# STM32N657 register map
File version: 1.0
CPU: CM55 r0p1, little endian, no MPU, FPU, vendor SysTick, 8 interrupt priority bits
Registers are 32-bit, read-write, reset 0x0 unless marked. A register's access mark holds for its fields unless they carry their own. Offsets are from the block's base; [hi:lo] are bit positions; {n}, {i} and the like mark numbered series; 'fields as' and 'values as' point back to an identical list.

## FDCAN1 — FDCAN register block
Base 0x4000A000
Same registers: FDCAN2 0x4000A400, FDCAN3 0x4000E800, FDCAN1_S 0x5000A000, FDCAN2_S 0x5000A400, FDCAN3_S 0x5000E800
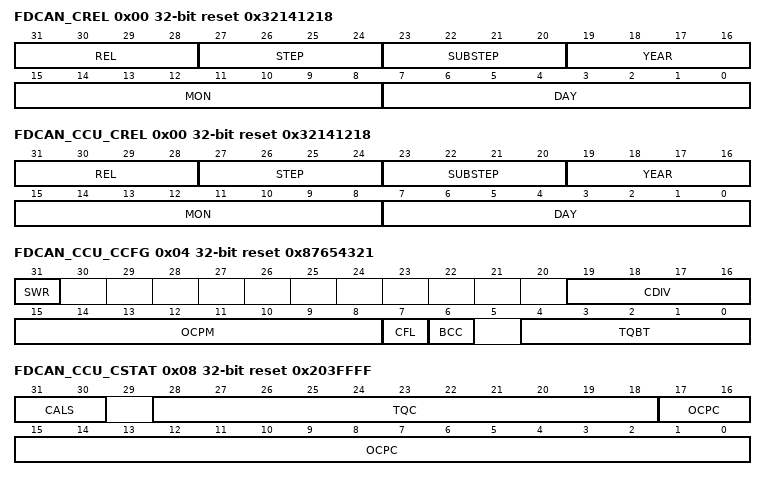
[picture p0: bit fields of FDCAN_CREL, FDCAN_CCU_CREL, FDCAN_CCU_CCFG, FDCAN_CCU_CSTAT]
0x00 FDCAN_CREL ro reset 0x32141218 — FDCAN core release register
  [31:28] REL — Core release = 3
  [27:24] STEP — Step of core release = 2
  [23:20] SUBSTEP — Sub-step of core release = 1
  [19:16] YEAR — Timestamp year = 4
  [15:8] MON — Timestamp month = 12
  [7:0] DAY — Timestamp day =18
0x00 FDCAN_CCU_CREL ro reset 0x32141218 (alternate view of FDCAN_CREL) — FDCAN core release register
  [31:28] REL — Core release = 1
  [27:24] STEP — Step of core release = 1
  [23:20] SUBSTEP — Sub-step of core release = 1
  [19:16] YEAR — Timestamp year =
  [15:8] MON — Timestamp month = 12
  [7:0] DAY — Timestamp day = 18
0x04 FDCAN_ENDN ro reset 0x87654321 — FDCAN Endian register
  [31:0] ETV — Endiannes Test value
0x04 FDCAN_CCU_CCFG reset 0x87654321 (alternate view of FDCAN_ENDN) — FDCAN Endian register
  [31] SWR — Software reset
  [19:16] CDIV — Clock divider
    0=Divide by 1; 1=Divide by 2; 2=Divide by 4; 3=Divide by 6; 4=Divide by 8; 5=Divide by 10; 6=Divide by 12; 7=Divide by 14; 8=Divide by 16; 9=Divide by 18; 10=Divide by 20; 11=Divide by 22; 12=Divide by 24; 13=Divide by 26; 14=Divide by 28; 15=Divide by 30
  [15:8] OCPM — Oscillator clock periods minimum
  [7] CFL — Calibration field length
    0=Calibration field length is 32 bits; 1=Calibration field length is 64 bits
  [6] BCC — Bypass clock calibration
    0=Clock calibration unit generates time quanta clock; 1=Clock calibration unit bypassed (default configuration)
  [4:0] TQBT — Time quanta per bit time
0x08 FDCAN_CCU_CSTAT ro reset 0x203FFFF — Calibration status register
  [31:30] CALS — Calibration state
    0=Not_Calibrated; 1=Basic_Calibrated; 2=Precision_Calibrated
  [28:18] TQC — Time quanta counter
  [17:0] OCPC — Oscillator clock period counter
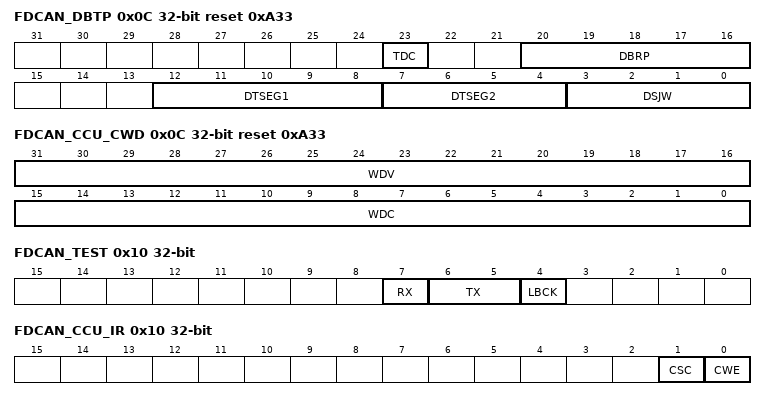
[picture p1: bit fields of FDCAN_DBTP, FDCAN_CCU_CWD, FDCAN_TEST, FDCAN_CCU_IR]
0x0C FDCAN_DBTP reset 0xA33 — FDCAN data bit timing and prescaler register
  [23] TDC — Transceiver delay compensation
    0=Transceiver delay compensation disabled; 1=Transceiver delay compensation enabled
  [20:16] DBRP — Data bitrate prescaler
  [12:8] DTSEG1 — Data time segment before sample point
  [7:4] DTSEG2 — Data time segment after sample point
  [3:0] DSJW — Synchronization jump width
0x0C FDCAN_CCU_CWD access per field reset 0xA33 (alternate view of FDCAN_DBTP) — FDCAN data bit timing and prescaler register
  [31:16] WDV ro — Watchdog value
  [15:0] WDC rw
0x10 FDCAN_TEST access per field
  [7] RX ro — Receive pin
    0=The CAN bus is dominant (FDCANx_RX = 0); 1=The CAN bus is recessive (FDCANx_RX = 1)
  [6:5] TX rw — Control of transmit pin
    0=Reset value , FDCANx_TX TX is controlled by the CAN core, updated at the end of the CAN bit time; 1=Sample point can be monitored at pin FDCANx_TX; 2=Dominant (0) level at pin FDCANx_TX; 3=Recessive (1) at pin FDCANx_TX
  [4] LBCK rw — Loop back mode
    0=Reset value, loop back mode is disabled; 1=Loop back mode is enabled (see Test modes)
0x10 FDCAN_CCU_IR (alternate view of FDCAN_TEST) — FDCAN test register
  [1] CSC — Calibration state changed
    0=Calibration state unchanged; 1=Calibration state has changed
  [0] CWE — Calibration watchdog event
    0=No calibration watchdog event; 1=Calibration watchdog event occurred
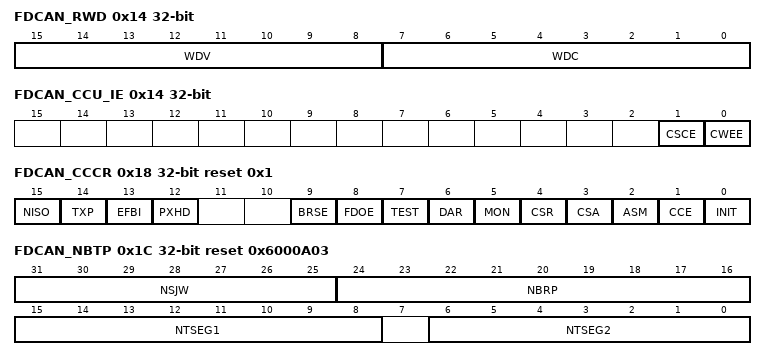
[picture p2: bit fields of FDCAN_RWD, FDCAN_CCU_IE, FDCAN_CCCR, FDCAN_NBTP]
0x14 FDCAN_RWD access per field — FDCAN RAM watchdog register
  [15:8] WDV ro — Watchdog value
  [7:0] WDC rw — Watchdog configuration
0x14 FDCAN_CCU_IE (alternate view of FDCAN_RWD) — FDCAN RAM watchdog register
  [1] CSCE — Calibration state changed enable
    0=Interrupt disabled; 1=Interrupt enabled
  [0] CWEE — Calibration watchdog event enable
    0=Interrupt disabled; 1=Interrupt enabled
0x18 FDCAN_CCCR access per field reset 0x1 — FDCAN CC control register
  [15] NISO rw — Non ISO operation
    0=CAN FD frame format according to ISO11898-1; 1=CAN FD frame format according to Bosch CAN FD Specification V1.0
  [14] TXP rw — If this bit is set, the FDCAN pauses for two CAN bit times before starting the next transmission after successfully transmitting a frame.
    0=Disabled; 1=Enabled
  [13] EFBI rw — Edge filtering during bus integration
    0=Edge filtering disabled; 1=Two consecutive dominant tq required to detect an edge for hard synchronization
  [12] PXHD rw — Protocol exception handling disable
    0=Protocol exception handling enabled; 1=Protocol exception handling disabled
  [9] BRSE rw — FDCAN bitrate switching
    0=Bitrate switching for transmissions disabled; 1=Bitrate switching for transmissions enabled
  [8] FDOE rw — FD operation enable
    0=FD operation disabled; 1=FD operation enabled
  [7] TEST rw — Test mode enable
    0=Normal operation, register TEST holds reset values; 1=Test mode, write access to register TEST enabled
  [6] DAR rw — Disable automatic retransmission
    0=Automatic retransmission of messages not transmitted successfully enabled; 1=Automatic retransmission disabled
  [5] MON rw — Bus monitoring mode
    0=Bus monitoring mode is disabled; 1=Bus monitoring mode is enabled
  [4] CSR rw — Clock stop request
    0=No clock stop is requested; 1=Clock stop requested. When clock stop is requested, first INIT and then CSA is set
  [3] CSA ro — Clock stop acknowledge
    0=No clock stop acknowledged; 1=FDCAN may be set in power down by stopping APB clock and kernel clock
  [2] ASM rw — ASM restricted operation mode
    0=Normal CAN operation; 1=Restricted operation mode active
  [1] CCE rw — Configuration change enable
    0=The CPU has no write access to the protected configuration registers; 1=The CPU has write access to the protected configuration registers (while FDCAN_CCCR.INIT = 1 CCE bit is automatically cleared when INIT bit is cleared)
  [0] INIT rw — Initialization
    0=Normal operation; 1=Initialization is started (while FDCAN_CCCR.INIT = 1 CCE bit is automatically cleared when INIT bit is cleared)
0x1C FDCAN_NBTP reset 0x6000A03 — FDCAN nominal bit timing and prescaler register
  [31:25] NSJW — Nominal (re)synchronization jump width
  [24:16] NBRP — Bitrate prescaler
  [15:8] NTSEG1 — Nominal time segment before sample point
  [6:0] NTSEG2 — Nominal time segment after sample point
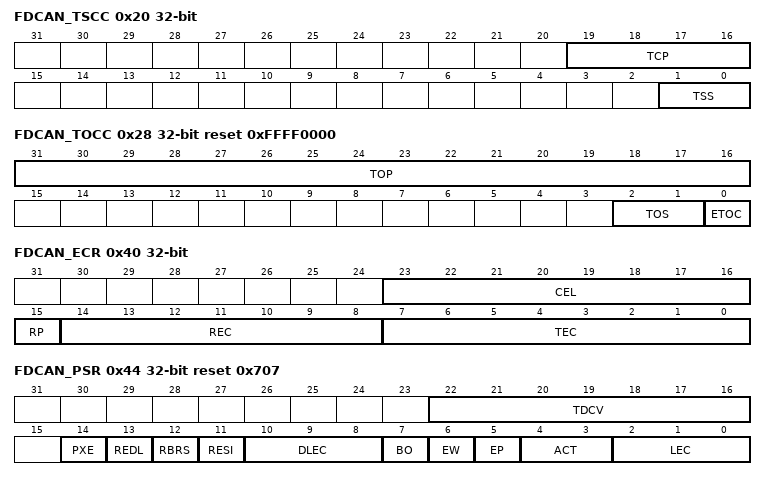
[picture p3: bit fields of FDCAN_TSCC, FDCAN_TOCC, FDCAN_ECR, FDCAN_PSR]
0x20 FDCAN_TSCC — FDCAN timestamp counter configuration register
  [19:16] TCP — Timestamp counter prescaler
  [1:0] TSS — Timestamp select
    0=Timestamp counter value always 0x0000; 1=Timestamp counter value incremented according to TCP; 2=External timestamp counter from TIM3 value used (tim3_cnt[0:15]); 3=Same as 00
0x24 FDCAN_TSCV — FDCAN timestamp counter value register
  [15:0] TSC — Timestamp counter
0x28 FDCAN_TOCC reset 0xFFFF0000 — FDCAN timeout counter configuration register
  [31:16] TOP — Timeout period
  [2:1] TOS — Timeout select
    0=Continuous operation; 1=Timeout controlled by Tx event FIFO; 2=Timeout controlled by Rx FIFO 0; 3=Timeout controlled by Rx FIFO 1
  [0] ETOC — Enable timeout counter
    0=Timeout counter disabled; 1=Timeout counter enabled
0x2C FDCAN_TOCV reset 0xFFFF — FDCAN timeout counter value register
  [15:0] TOC — Timeout counter
0x40 FDCAN_ECR access per field — FDCAN error counter register
  [23:16] CEL rw — CAN error logging
  [15] RP ro — Receive error passive
    0=The receive error counter is below the error passive level of 128; 1=The receive error counter has reached the error passive level of 128
  [14:8] REC ro — Receive error counter
  [7:0] TEC ro — Transmit error counter
0x44 FDCAN_PSR access per field reset 0x707 — FDCAN protocol status register
  [22:16] TDCV ro — Transmitter delay compensation value
  [14] PXE rw — Protocol exception event
    0=No protocol exception event occurred since last read access; 1=Protocol exception event occurred
  [13] REDL rw — Received FDCAN message
    0=Since this bit was reset by the CPU, no FDCAN message has been received; 1=Message in FDCAN format with EDL flag set has been received
  [12] RBRS rw — BRS flag of last received FDCAN message
    0=Last received FDCAN message did not have its BRS flag set; 1=Last received FDCAN message had its BRS flag set
  [11] RESI rw — ESI flag of last received FDCAN message
    0=Last received FDCAN message did not ha ve its ESI flag set; 1=Last received FDCAN message had its ESI flag set
  [10:8] DLEC ro — Data last error code
  [7] BO ro — Bus_Off status
    0=The FDCAN is not Bus_Off; 1=The FDCAN is in Bus_Off state
  [6] EW ro — Warning status
    0=Both error counters are below the Error_Warning limit of 96; 1=At least one of error counter has reached the Error_Warning limit of 96
  [5] EP ro — Error passive
    0=The FDCAN is in the Error_Active state. It normally takes part in bus communication and sends an active error flag when an error has been detected; 1=The FDCAN is in the Error_Passive state
  [4:3] ACT ro — Activity
    0=Synchronizing: node is synchronizing on CAN communication; 1=Idle: node is neither receiver nor transmitter; 2=Receiver: node is operating as receiver; 3=Transmitter: node is operating as transmitter
  [2:0] LEC ro — Last error code
    0=No error: No error occurred since LEC has been reset by successful reception or transmission; 1=Stuff error: More than 5 equal bits in a sequence have occurred in a part of a received message where this is not allowed; 2=Form error: A fixed format part of a received frame has the wrong format; 3=AckError: The message transmitted by the FDCAN was not acknowledged by another node; 4=Bit1Error: During the transmission of a message (with the exception of the arbitration field), the device wanted to send a recessive level (bit of logical value 1), but the monitored bus value was dominant; 5=Bit0Error: During the transmission of a message (or acknowledge bit, or active error flag, or overload flag), the device wanted to send a dominant level (data or identifier bit logical value 0), but the monitored bus value was recessive. During Bus_Off recovery this status is set each time a sequence of 11 recessive bits has been monitored. This enables the CPU to monitor the proceeding of the Bus_Off recovery sequence (indicating the bus is not stuck at dominant or continuously disturbed).; 6=CRCError: The CRC check sum of a received message was incorrect. The CRC of an incoming message does not match with the CRC calculated from the received data.; 7=NoChange: Any read access to the protocol status register re-initializes the LEC to 7. When the LEC shows the value 7, no CAN bus event was detected since the last CPU read access to the protocol status register.
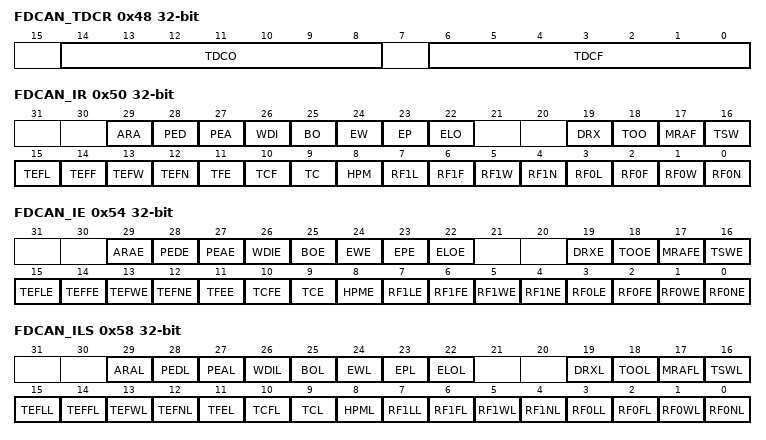
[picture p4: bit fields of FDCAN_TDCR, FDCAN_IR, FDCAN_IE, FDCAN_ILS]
0x48 FDCAN_TDCR — FDCAN transmitter delay compensation register
  [14:8] TDCO — Transmitter delay compensation offset
  [6:0] TDCF — Transmitter delay compensation filter window length
0x50 FDCAN_IR — FDCAN interrupt register
  [29] ARA — Access to reserved address
    0=No access to reserved address occurred; 1=Access to reserved address occurred
  [28] PED — Protocol error in data phase (data bit time is used)
    0=No protocol error in data phase; 1=Protocol error in data phase detected (PSR.DLEC different from 0,7)
  [27] PEA — Protocol error in arbitration phase (nominal bit time is used)
    0=No protocol error in arbitration phase; 1=Protocol error in arbitration phase detected (PSR.LEC different from 0,7)
  [26] WDI — Watchdog interrupt
    0=No message RAM watchdog event occurred; 1=Message RAM watchdog event due to missing READY
  [25] BO — Bus_Off status
    0=Bus_Off status unchanged; 1=Bus_Off status changed
  [24] EW — Warning status
    0=Error_Warning status unchanged; 1=Error_Warning status changed
  [23] EP — Error passive
    0=Error_Passive status unchanged; 1=Error_Passive status changed
  [22] ELO — Error logging overflow
    0=CAN error logging counter did not overflow; 1=Overflow of CAN error logging counter occurred
  [19] DRX — Message stored to dedicated Rx buffer
    0=No Rx buffer updated; 1=At least one received message stored into a Rx buffer
  [18] TOO — Timeout occurred
    0=No timeout; 1=Timeout reached
  [17] MRAF — Message RAM access failure
    0=No message RAM access failure occurred; 1=Message RAM access failure occurred
  [16] TSW — Timestamp wraparound
    0=No timestamp counter wraparound; 1=Timestamp counter wraparound
  [15] TEFL — Tx event FIFO element lost
    0=No Tx event FIFO element lost; 1=Tx event FIFO element lost, also set after write attempt to Tx event FIFO of size 0
  [14] TEFF — Tx event FIFO full
    0=Tx event FIFO not full; 1=Tx event FIFO full
  [13] TEFW — Tx event FIFO watermark reached
    0=Tx event FIFO fill level below watermark; 1=Tx event FIFO fill level reached watermark
  [12] TEFN — Tx event FIFO new entry
    0=Tx event FIFO unchanged; 1=Tx handler wrote Tx event FIFO element
  [11] TFE — Tx FIFO empty
    0=Tx FIFO non-empty; 1=Tx FIFO empty
  [10] TCF — Transmission cancellation finished
    0=No transmission cancellation finished; 1=Transmission cancellation finished
  [9] TC — Transmission completed
    0=No transmission completed; 1=Transmission completed
  [8] HPM — High priority message
    0=No high priority message received; 1=High priority message received
  [7] RF1L — Rx FIFO 1 message lost
    0=No Rx FIFO 1 message lost; 1=Rx FIFO 1 message lost, also set after write attempt to Rx FIFO 1 of size 0
  [6] RF1F — Rx FIFO 1 full
    0=Rx FIFO 1 not full; 1=Rx FIFO 1 full
  [5] RF1W — Rx FIFO 1 watermark reached
    0=Rx FIFO 1 fill level below watermark; 1=Rx FIFO 1 fill level reached watermark
  [4] RF1N — Rx FIFO 1 new message
    0=No new message written to Rx FIFO 1; 1=New message written to Rx FIFO 1
  [3] RF0L — Rx FIFO 0 message lost
    0=No Rx FIFO 0 message lost; 1=Rx FIFO 0 message lost, also set after write attempt to Rx FIFO 0 of size 0
  [2] RF0F — Rx FIFO 0 full
    0=Rx FIFO 0 not full; 1=Rx FIFO 0 full
  [1] RF0W — Rx FIFO 0 watermark reached
    0=Rx FIFO 0 fill level below watermark; 1=Rx FIFO 0 fill level reached watermark
  [0] RF0N — Rx FIFO 0 New message
    0=No new message written to Rx FIFO 0; 1=New message written to Rx FIFO 0
0x54 FDCAN_IE — FDCAN interrupt enable register
  [29] ARAE — Access to Reserved address enable
  [28] PEDE — Protocol error in data phase enable
  [27] PEAE — Protocol error in Arbitration phase enable
  [26] WDIE — Watchdog interrupt enable
    0=Interrupt disabled; 1=Interrupt enabled
  [25] BOE — Bus_Off status
    0=Interrupt disabled; 1=Interrupt enabled
  [24] EWE — Warning status interrupt enable
    0=Interrupt disabled; 1=Interrupt enabled
  [23] EPE — Error passive interrupt enable
    0=Interrupt disabled; 1=Interrupt enabled
  [22] ELOE — Error logging overflow interrupt enable
    0=Interrupt disabled; 1=Interrupt enabled
  [19] DRXE — Message stored to dedicated Rx buffer interrupt enable
    0=Interrupt disabled; 1=Interrupt enabled
  [18] TOOE — Timeout occurred interrupt enable
    0=Interrupt disabled; 1=Interrupt enabled
  [17] MRAFE — Message RAM access failure interrupt enable
    0=Interrupt disabled; 1=Interrupt enabled
  [16] TSWE — Timestamp wraparound interrupt enable
    0=Interrupt disabled; 1=Interrupt enabled
  [15] TEFLE — Tx event FIFO element lost interrupt enable
    0=Interrupt disabled; 1=Interrupt enabled
  [14] TEFFE — Tx event FIFO full interrupt enable
    0=Interrupt disabled; 1=Interrupt enabled
  [13] TEFWE — Tx event FIFO watermark reached interrupt enable
    0=Interrupt disabled; 1=Interrupt enabled
  [12] TEFNE — Tx event FIFO new entry interrupt enable
    0=Interrupt disabled; 1=Interrupt enabled
  [11] TFEE — Tx FIFO empty interrupt enable
    0=Interrupt disabled; 1=Interrupt enabled
  [10] TCFE — Transmission cancellation finished interrupt enable
    0=Interrupt disabled; 1=Interrupt enabled
  [9] TCE — Transmission completed interrupt enable
    0=Interrupt disabled; 1=Interrupt enabled
  [8] HPME — High priority message interrupt enable
    0=Interrupt disabled; 1=Interrupt enabled
  [7] RF1LE — Rx FIFO 1 message lost interrupt enable
    0=Interrupt disabled; 1=Interrupt enabled
  [6] RF1FE — Rx FIFO 1 full interrupt enable
    0=Interrupt disabled; 1=Interrupt enabled
  [5] RF1WE — Rx FIFO 1 watermark reached interrupt enable
    0=Interrupt disabled; 1=Interrupt enabled
  [4] RF1NE — Rx FIFO 1 new message interrupt enable
    0=Interrupt disabled; 1=Interrupt enabled
  [3] RF0LE — Rx FIFO 0 message lost interrupt enable
    0=Interrupt disabled; 1=Interrupt enabled
  [2] RF0FE — Rx FIFO 0 full interrupt enable
    0=Interrupt disabled; 1=Interrupt enabled
  [1] RF0WE — Rx FIFO 0 watermark reached interrupt enable
    0=Interrupt disabled; 1=Interrupt enabled
  [0] RF0NE — Rx FIFO 0 new message interrupt enable
    0=Interrupt disabled; 1=Interrupt enabled
0x58 FDCAN_ILS — FDCAN interrupt line select register
  [29] ARAL — Access to reserved address line
  [28] PEDL — Protocol error in data phase line
  [27] PEAL — Protocol error in arbitration phase line
  [26] WDIL — Watchdog interrupt line
  [25] BOL — Bus_Off status
  [24] EWL — Warning status interrupt line
  [23] EPL — Error passive interrupt line
  [22] ELOL — Error logging overflow interrupt line
  [19] DRXL — Message stored to dedicated Rx buffer interrupt line
  [18] TOOL — Timeout occurred interrupt line
  [17] MRAFL — Message RAM access failure interrupt line
  [16] TSWL — Timestamp wraparound interrupt line
  [15] TEFLL — Tx event FIFO element Lost interrupt line
  [14] TEFFL — Tx event FIFO full interrupt line
  [13] TEFWL — Tx event FIFO watermark reached interrupt line
  [12] TEFNL — Tx event FIFO new entry interrupt line
  [11] TFEL — Tx FIFO empty interrupt line
  [10] TCFL — Transmission cancellation finished interrupt line
  [9] TCL — Transmission completed interrupt line
  [8] HPML — High priority message interrupt line
  [7] RF1LL — Rx FIFO 1 message lost interrupt line
  [6] RF1FL — Rx FIFO 1 full interrupt line
  [5] RF1WL — Rx FIFO 1 watermark reached interrupt line
  [4] RF1NL — Rx FIFO 1 new message interrupt line
  [3] RF0LL — Rx FIFO 0 message lost interrupt line
  [2] RF0FL — Rx FIFO 0 full interrupt line
  [1] RF0WL — Rx FIFO 0 watermark reached interrupt line
  [0] RF0NL — Rx FIFO 0 new message interrupt line
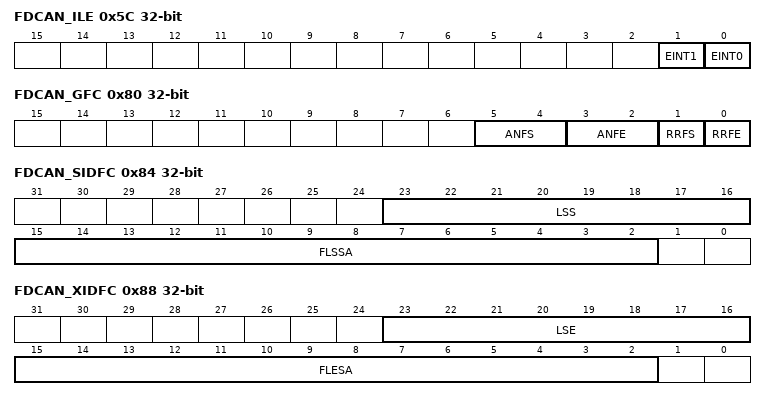
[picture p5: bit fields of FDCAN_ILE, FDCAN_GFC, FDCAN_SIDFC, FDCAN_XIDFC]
0x5C FDCAN_ILE — FDCAN interrupt line enable register
  [1] EINT1 — Enable interrupt line 1
    0=Interrupt line fdcan_intr1_it disabled; 1=Interrupt line fdcan_intr1_it enabled
  [0] EINT0 — Enable interrupt line 0
    0=Interrupt line fdcan_intr0_it disabled; 1=Interrupt line fdcan_intr0_it enabled
0x80 FDCAN_GFC — FDCAN global filter configuration register
  [5:4] ANFS — Accept non-matching frames standard
    0=Accept in Rx FIFO 0; 1=Accept in Rx FIFO 1; 2=Reject; 3=Reject
  [3:2] ANFE — Accept non-matching frames extended
    values as ANFS
  [1] RRFS — Reject remote frames standard
    0=Filter remote frames with 11-bit standard ID; 1=Reject all remote frames with 11-bit standard ID
  [0] RRFE — Reject remote frames extended
    0=Filter remote frames with 29-bit standard ID; 1=Reject all remote frames with 29-bit standard ID
0x84 FDCAN_SIDFC — FDCAN standard ID filter configuration register
  [23:16] LSS — List size standard
    0=No standard message ID filter
  [15:2] FLSSA — Filter list standard start address
0x88 FDCAN_XIDFC — FDCAN extended ID filter configuration register
  [23:16] LSE — List size extended
    0=No extended message ID filter
  [15:2] FLESA — Filter list extended start address
0x90 FDCAN_XIDAM reset 0x1FFFFFFF — FDCAN extended ID and mask register
  [28:0] EIDM — Extended ID Mask
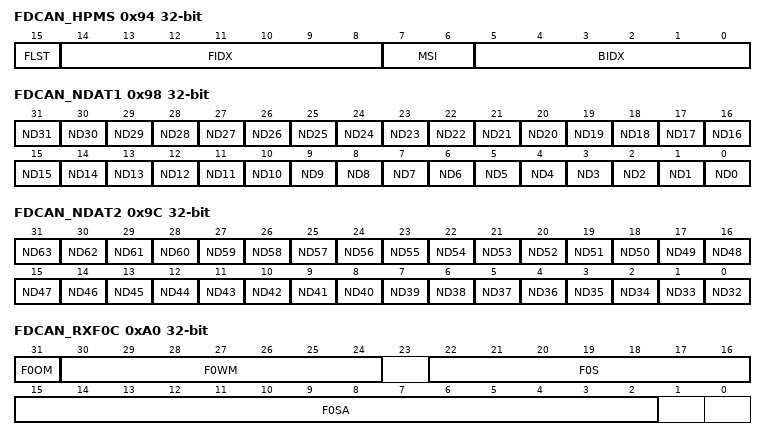
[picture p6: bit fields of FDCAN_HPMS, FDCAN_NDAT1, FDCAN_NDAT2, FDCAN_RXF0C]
0x94 FDCAN_HPMS ro — FDCAN high priority message status register
  [15] FLST — Filter list
    0=Standard filter list; 1=Extended filter list
  [14:8] FIDX — Filter index
  [7:6] MSI — Message storage indicator
    0=No FIFO selected; 1=FIFO overrun; 2=Message stored in FIFO 0; 3=Message stored in FIFO 1
  [5:0] BIDX — Buffer index
0x98 FDCAN_NDAT1 — FDCAN new data 1 register
  [all] fields
    0=Rx buffer not updated; 1=Rx buffer updated from new message
  [n] ND{n} (n=0..31) — New data[31:0]
0x9C FDCAN_NDAT2 — FDCAN new data 2 register
  [all] fields
    values as the fields of FDCAN_NDAT1
  [n-32] ND{n} (n=32..63) — New data[63:32]
0xA0 FDCAN_RXF0C — FDCAN Rx FIFO 0 configuration register
  [31] F0OM — FIFO 0 operation mode
    0=FIFO 0 blocking mode; 1=FIFO 0 overwrite mode
  [30:24] F0WM — FIFO 0 watermark
    0=Watermark interrupt disabled
  [22:16] F0S — Rx FIFO 0 size
    0=No Rx FIFO 0
  [15:2] F0SA — Rx FIFO 0 start address
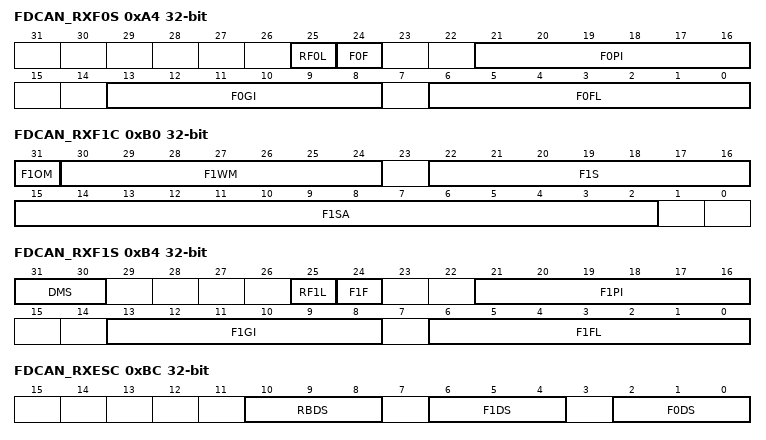
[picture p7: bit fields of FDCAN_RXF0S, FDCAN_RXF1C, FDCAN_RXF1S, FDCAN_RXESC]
0xA4 FDCAN_RXF0S — FDCAN Rx FIFO 0 status register
  [25] RF0L — Rx FIFO 0 message lost
    values as FDCAN_IR.RF0L
  [24] F0F — Rx FIFO 0 full
    0=Rx FIFO 0 not full; 1=Rx FIFO 0 full
  [21:16] F0PI — Rx FIFO 0 put index
  [13:8] F0GI — Rx FIFO 0 get index
  [6:0] F0FL — Rx FIFO 0 fill level
0xA8 FDCAN_RXF0A — FDCAN Rx FIFO 0 acknowledge register
  [5:0] F0AI — Rx FIFO 0 acknowledge index
0xAC FDCAN_RXBC — FDCAN Rx buffer configuration register
  [15:2] RBSA — Rx buffer start address
0xB0 FDCAN_RXF1C — FDCAN Rx FIFO 1 configuration register
  [31] F1OM — FIFO 1 operation mode
    0=FIFO 1 blocking mode; 1=FIFO 1 overwrite mode
  [30:24] F1WM — Rx FIFO 1 watermark
    0=Watermark interrupt disabled
  [22:16] F1S — Rx FIFO 1 size
    0=No Rx FIFO 1
  [15:2] F1SA — Rx FIFO 1 start address
0xB4 FDCAN_RXF1S ro — FDCAN Rx FIFO 1 status register
  [31:30] DMS — Debug message status
    0=Idle state, wait for reception of debug messages; 1=Debug message A received; 2=Debug messages A, B received; 3=Debug messages A, B, C received
  [25] RF1L — Rx FIFO 1 message lost
    values as FDCAN_IR.RF1L
  [24] F1F — Rx FIFO 1 full
    0=Rx FIFO 1 not full; 1=Rx FIFO 1 full
  [21:16] F1PI — Rx FIFO 1 put index
  [13:8] F1GI — Rx FIFO 1 get index
  [6:0] F1FL — Rx FIFO 1 fill level
0xB8 FDCAN_RXF1A — FDCAN Rx FIFO 1 acknowledge register
  [5:0] F1AI — Rx FIFO 1 acknowledge index
0xBC FDCAN_RXESC ro — FDCAN Rx buffer element size configuration register
  [all] fields
    0=8-byte data field; 1=12-byte data field; 2=16-byte data field; 3=20-byte data field; 4=24-byte data field; 5=32-byte data field; 6=48-byte data field; 7=64-byte data field
  [10:8] RBDS — Rx buffer data field size
  [6:4] F1DS — Rx FIFO 0 data field size
  [2:0] F0DS — Rx FIFO 1 data field size
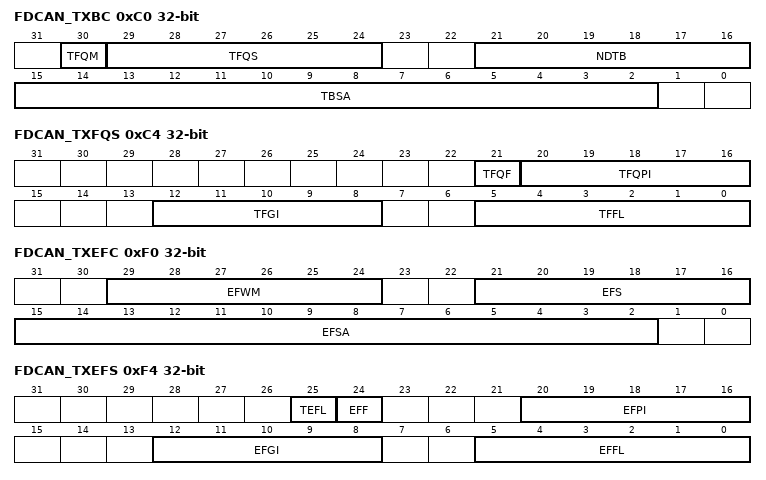
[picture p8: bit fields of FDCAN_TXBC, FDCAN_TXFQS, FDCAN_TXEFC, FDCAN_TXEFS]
0xC0 FDCAN_TXBC — FDCAN Tx buffer configuration register
  [30] TFQM — Tx FIFO/queue mode
    0=Tx FIFO operation; 1=Tx queue operation
  [29:24] TFQS — Transmit FIFO/queue size
    0=No Tx FIFO/queue
  [21:16] NDTB — Number of dedicated transmit buffers
    0=No dedicated Tx buffers
  [15:2] TBSA — Tx buffers start address
0xC4 FDCAN_TXFQS ro — FDCAN Tx FIFO/queue status register
  [21] TFQF — Tx FIFO/queue full
  [20:16] TFQPI — Tx FIFO/queue put index
  [12:8] TFGI — Tx FIFO get index.
  [5:0] TFFL — Tx FIFO free level
0xC8 FDCAN_TXESC ro — FDCAN Tx buffer element size configuration register
  [2:0] TBDS — Tx buffer data Field size:
    values as the fields of FDCAN_RXESC
0xCC FDCAN_TXBRP ro — FDCAN Tx buffer request pending register
  [31:0] TRP — Transmission request pending
    0=No transmission request pending; 1=Transmission request pending
0xD0 FDCAN_TXBAR — FDCAN Tx buffer add request register
  [31:0] AR — Add request
    0=No transmission request added; 1=Transmission requested added
0xD4 FDCAN_TXBCR — FDCAN Tx buffer cancellation request register
  [31:0] CR — Cancellation request
    0=No cancellation pending; 1=Cancellation pending
0xD8 FDCAN_TXBTO ro — FDCAN Tx buffer transmission occurred register
  [31:0] TO — Transmission occurred
    0=No transmission occurred; 1=Transmission occurred
0xDC FDCAN_TXBCF ro — FDCAN Tx buffer cancellation finished register
  [31:0] CF — Cancellation finished
    0=No transmit buffer cancellation; 1=Transmit buffer cancellation finished
0xE0 FDCAN_TXBTIE — FDCAN Tx buffer transmission interrupt enable register
  [31:0] TIE — Transmission interrupt enable
    0=Transmission interrupt disabled; 1=Transmission interrupt enable
0xE4 FDCAN_TXBCIE — FDCAN Tx buffer cancellation finished interrupt enable register
  [31:0] CFIE — Cancellation finished interrupt enable
    0=Cancellation finished interrupt disabled; 1=Cancellation finished interrupt enabled
0xF0 FDCAN_TXEFC — FDCAN Tx event FIFO configuration register
  [29:24] EFWM — Event FIFO watermark
    0=Watermark interrupt disabled
  [21:16] EFS — Event FIFO size.
    0=Tx event FIFO disabled
  [15:2] EFSA — Event FIFO start address
0xF4 FDCAN_TXEFS ro — FDCAN Tx event FIFO status register
  [25] TEFL — Tx event FIFO element lost
  [24] EFF — Event FIFO full
    0=Tx event FIFO not full; 1=Tx event FIFO full
  [20:16] EFPI — Event FIFO put index
  [12:8] EFGI — Event FIFO get index
  [5:0] EFFL — Event FIFO fill level
0xF8 FDCAN_TXEFA — FDCAN Tx event FIFO acknowledge register
  [4:0] EFAI — Event FIFO acknowledge index
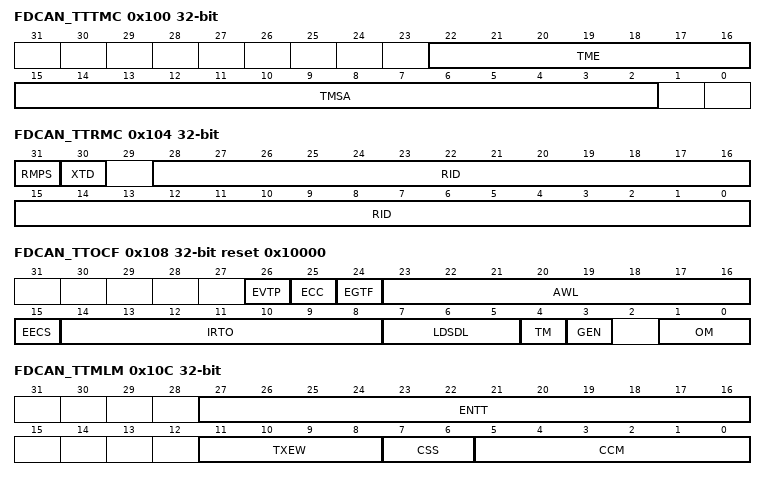
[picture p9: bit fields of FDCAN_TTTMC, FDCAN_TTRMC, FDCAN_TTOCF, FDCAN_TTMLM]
0x100 FDCAN_TTTMC — FDCAN TT trigger memory configuration register
  [22:16] TME — Trigger memory elements
    0=No trigger memory
  [15:2] TMSA — Trigger memory start address.
0x104 FDCAN_TTRMC — FDCAN TT reference message configuration register
  [31] RMPS — Reference message payload select
    0=Reference message has no additional payload; 1=The following elements are taken from Tx buffer 0:
  [30] XTD — Extended identifier
    0=11-bit standard identifier; 1=29-bit extended identifier
  [28:0] RID — Reference identifier.
0x108 FDCAN_TTOCF reset 0x10000 — FDCAN TT operation configuration register
  [26] EVTP — Event trigger polarity.
    0=Rising edge trigger; 1=Falling edge trigger
  [25] ECC — Enable clock calibration.
    0=Automatic clock calibration in FDCAN level 0, 2 is disabled; 1=Automatic clock calibration in FDCAN level 0, 2 is enabled
  [24] EGTF — Enable global time filtering.
    0=Global time filtering in FDCAN level 0, 2 is disabled; 1=Global time filtering in FDCAN level 0, 2 is enabled
  [23:16] AWL — Application watchdog limit.
  [15] EECS — Enable external clock synchronization
    0=External clock synchronization in FDCAN level 0, 2 disabled; 1=External clock synchronization in FDCAN level 0, 2 enabled
  [14:8] IRTO — Initial reference trigger offset.
  [7:5] LDSDL — LD of synchronization deviation limit.
  [4] TM — Time master.
    0=Time master function disabled; 1=Potential time master
  [3] GEN — Gap enable.
    0=Strictly time-triggered operation; 1=External event-synchronized time-triggered operation
  [1:0] OM — Operation mode.
    0=Event-driven CAN communication, default; 1=TTCAN level 1; 2=TTCAN level 2; 3=TTCAN level 0
0x10C FDCAN_TTMLM — FDCAN TT matrix limits register
  [27:16] ENTT — Expected number of Tx triggers
  [11:8] TXEW — Tx enable window
  [7:6] CSS — Cycle start synchronization
    0=No sync pulse; 1=Sync pulse at start of basic cycle; 2=Sync pulse at start of matrix cycle
  [5:0] CCM — Cycle count Max
    0=1 basic cycle per matrix cycle; 1=2 basic cycles per matrix cycle; 3=4 basic cycles per matrix cycle; 7=8 basic cycles per matrix cycle; 15=16 basic cycles per matrix cycle; 31=32 basic cycles per matrix cycle; 63=64 basic cycles per matrix cycle
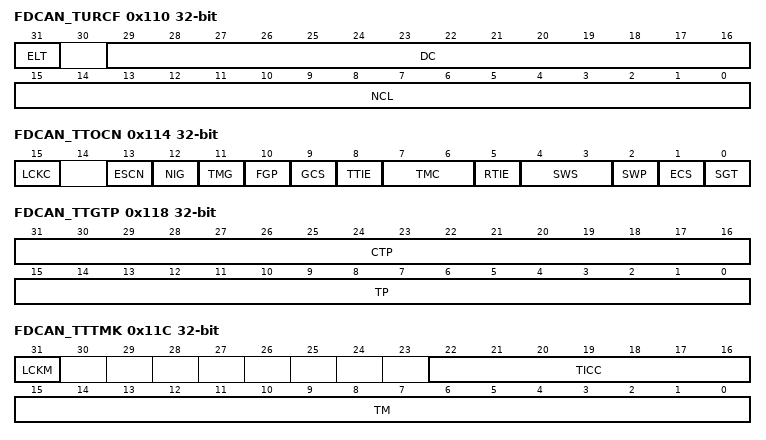
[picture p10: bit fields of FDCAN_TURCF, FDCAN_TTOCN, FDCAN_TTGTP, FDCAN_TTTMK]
0x110 FDCAN_TURCF — FDCAN TUR configuration register
  [31] ELT — Enable local time.
    0=Local time is stopped, default; 1=Local time is enabled
  [29:16] DC — Denominator configuration.
    0=Illegal value
  [15:0] NCL — Numerator configuration low.
0x114 FDCAN_TTOCN access per field — FDCAN TT operation control register
  [15] LCKC ro — TT operation control register locked.
    0=Write access to FDCAN_TTOCN enabled; 1=Write access to FDCAN_TTOCN locked
  [13] ESCN rw — External synchronization control
    0=External synchronization disabled; 1=External synchronization enabled
  [12] NIG rw — Next is gap.
    0=No action, reset by reception of any reference message; 1=Transmit next reference message with Next_is_Gap = 1
  [11] TMG rw — Time mark gap.
    0=Reset by each reference message; 1=Next reference message started when register time mark interrupt FDCAN_TTIR.RTMI is activated
  [10] FGP rw — Finish gap.
    0=No reference message requested; 1=Application requested start of reference message
  [9] GCS rw — Gap control select
    0=Gap control independent from event trigger; 1=Gap control by input event trigger pin
  [8] TTIE rw — Trigger time mark interrupt pulse enable
    0=Trigger time mark interrupt output fdcan1_tmp for more than one instance and fdcan_tmp if only one instance disabled; 1=Trigger time mark interrupt output fdcan1_tmp for more than one instance and fdcan_tmp if only one instance enabled
  [7:6] TMC rw — Register time mark compare.
    0=No Register time mark interrupt generated; 1=Register time mark interrupt if time mark = cycle time; 2=Register time mark interrupt if time mark = local time; 3=Register time mark interrupt if time mark = global time
  [5] RTIE rw — Register time mark interrupt pulse enable.
    0=Register time mark interrupt output disabled; 1=Register time mark interrupt output enabled
  [4:3] SWS rw — Stop watch source.
    0=Stop watch disabled; 1=Actual value of cycle time is copied to FDCAN_TTCPT.SWV; 2=Actual value of local time is copied to FDCAN_TTCPT.SWV; 3=Actual value of global time is copied to FDCAN_TTCPT.SWV
  [2] SWP rw — Stop watch polarity.
    0=Rising edge trigger; 1=Falling edge trigger
  [1] ECS rw — External clock synchronization.
  [0] SGT rw — Set global time.
0x118 FDCAN_TTGTP — FDCAN TT global time preset register
  [31:16] CTP — Cycle time target phase
  [15:0] TP — Time preset
0x11C FDCAN_TTTMK access per field — FDCAN TT time mark register
  [31] LCKM ro — TT time mark register locked
    0=Write access to FDCAN_TTTMK enabled; 1=Write access to FDCAN_TTTMK locked
  [22:16] TICC rw — Time mark cycle code
  [15:0] TM rw — Time mark
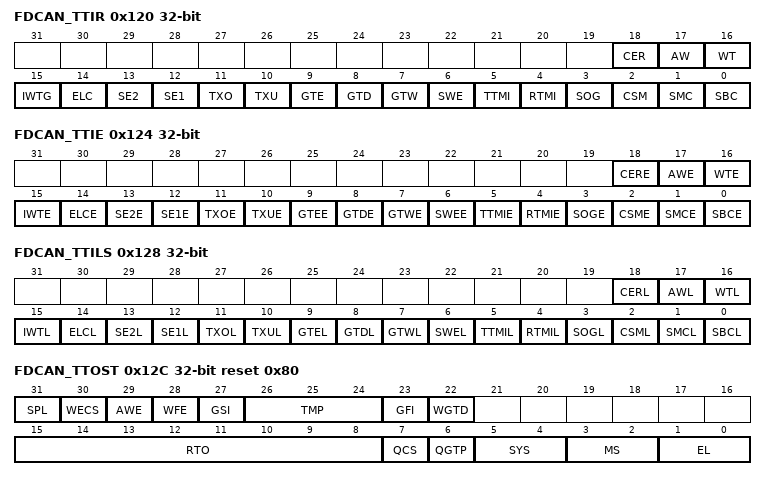
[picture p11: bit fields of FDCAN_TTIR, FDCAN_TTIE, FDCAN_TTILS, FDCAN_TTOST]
0x120 FDCAN_TTIR — FDCAN TT interrupt register
  [18] CER — Configuration error
    0=No error found in trigger list; 1=Error found in trigger list
  [17] AW — Application watchdog
    0=Application watchdog served in time; 1=Application watchdog not served in time
  [16] WT — Watch trigger
    0=No missing reference message; 1=Missing reference message (level 0: cycle time 0xFF00)
  [15] IWTG — Initialization watch trigger
  [14] ELC — Error level changed
    0=No change in error level; 1=Error level changed
  [13] SE2 — Scheduling error 2
    0=No scheduling error 2; 1=Scheduling error 2 occurred
  [12] SE1 — Scheduling error 1
    0=No scheduling error 1; 1=Scheduling error 1 occurred
  [11] TXO — Tx count overflow
    0=Number of Tx trigger as expected; 1=More Tx trigger than expected in one cycle
  [10] TXU — Tx count underflow
    0=Number of Tx trigger as expected; 1=Less Tx trigger than expected in one cycle
  [9] GTE — Global time error
    0=Synchronization deviation within limit; 1=Synchronization deviation exceeded limit
  [8] GTD — Global time discontinuity
    0=No discontinuity of global time; 1=Discontinuity of global time
  [7] GTW — Global time wrap
    0=No global time wrap occurred; 1=Global time wrap from 0xFFFF to 0x0000 occurred
  [6] SWE — Stop watch event
    0=No rising/falling edge at stop watch trigger pin detected; 1=Rising/falling edge at stop watch trigger pin detected
  [5] TTMI — Trigger time mark event internal
    0=Time mark not reached; 1=Time mark reached (level 0: cycle time FDCAN_TTOCF.RTO x 0x200)
  [4] RTMI — Register time mark interrupt
    0=Time mark not reached; 1=Time mark reached
  [3] SOG — Start of gap
  [2] CSM — Change of synchronization mode
    0=No change in master to slave relation or schedule synchronization; 1=Master to slave relation or schedule synchronization changed,
  [1] SMC — Start of matrix cycle
    0=No matrix cycle started since bit has been reset; 1=Matrix cycle started
  [0] SBC — Start of basic cycle
    0=No basic cycle started since bit has been reset; 1=Basic cycle started
0x124 FDCAN_TTIE — FDCAN TT interrupt enable register
  [all] fields
    0=TT interrupt disabled; 1=TT interrupt enabled
  [18] CERE — Configuration error interrupt enable
  [17] AWE — Application watchdog interrupt enable
  [16] WTE — Watch trigger interrupt enable
  [15] IWTE — Initialization watch trigger interrupt enable
  [14] ELCE — Change error level interrupt enable
  [13] SE2E — Scheduling error 2 interrupt enable
  [12] SE1E — Scheduling error 1 interrupt enable
  [11] TXOE — Tx count overflow interrupt enable
  [10] TXUE — Tx count underflow interrupt enable
  [9] GTEE — Global time error interrupt enable
  [8] GTDE — Global time discontinuity interrupt enable
  [7] GTWE — Global time wrap interrupt enable
  [6] SWEE — Stop watch event interrupt enable
  [5] TTMIE — Trigger time mark event internal interrupt enable
  [4] RTMIE — Register time mark interrupt enable
  [3] SOGE — Start of gap interrupt enable
  [2] CSME — Change of synchronization mode interrupt enable
  [1] SMCE — Start of matrix cycle interrupt enable
  [0] SBCE — Start of basic cycle interrupt enable
0x128 FDCAN_TTILS — FDCAN TT interrupt line select register
  [all] fields
    0=TT interrupt assigned to interrupt line 0; 1=TT interrupt assigned to interrupt line 1
  [18] CERL — Configuration error interrupt line
  [17] AWL — Application watchdog interrupt line
  [16] WTL — Watch trigger interrupt line
  [15] IWTL — Initialization watch trigger interrupt line
  [14] ELCL — Change error level interrupt line
  [13] SE2L — Scheduling error 2 interrupt line
  [12] SE1L — Scheduling error 1 interrupt line
  [11] TXOL — Tx count overflow interrupt line
  [10] TXUL — Tx count underflow interrupt line
  [9] GTEL — Global time error interrupt line
  [8] GTDL — Global time discontinuity interrupt line
  [7] GTWL — Global time wrap interrupt line
  [6] SWEL — Stop watch event interrupt line
  [5] TTMIL — Trigger time mark event internal interrupt line
  [4] RTMIL — Register time mark interrupt line
  [3] SOGL — Start of gap interrupt line
  [2] CSML — Change of synchronization mode interrupt line
  [1] SMCL — Start of matrix cycle interrupt line
  [0] SBCL — Start of basic cycle interrupt line
0x12C FDCAN_TTOST ro reset 0x80 — FDCAN TT operation status register
  [31] SPL — Schedule phase lock
    0=Phase outside range; 1=Phase inside range
  [30] WECS — Wait for external clock synchronization.
    0=No external clock synchronization pending; 1=Node waits for external clock synchronization to take effect. The bit is reset at the start of the next basic cycle.
  [29] AWE — Application watchdog event
    0=Application watchdog served in time; 1=Failed to serve application watchdog in time
  [28] WFE — Wait for event
    0=No gap announced, reset by a reference message with Next_is_Gap = 0; 1=Reference message with Next_is_Gap = 1 received
  [27] GSI — Gap started indicator
    0=No gap in schedule, reset by each reference message and for all time slaves; 1=Gap time after basic cycle has started
  [26:24] TMP — Time master priority
  [23] GFI — Gap finished indicator
    0=Reset at the end of each reference message; 1=Gap finished by FDCAN
  [22] WGTD — Wait for global time discontinuity
    0=No global time preset pending; 1=Node waits for the global time preset to take effect. The bit is reset when the node has transmitted a reference message with Disc_Bit = 1 or after it received a reference message.
  [15:8] RTO — Reference trigger offset
  [7] QCS — Quality of clock speed
    0=Local clock speed not synchronized to time master clock speed; 1=Synchronization deviation less than or equal to SDL
  [6] QGTP — Quality of global time phase
    0=Global time not valid; 1=Global time in phase with time master
  [5:4] SYS — Synchronization state
    0=Out of Synchronization; 1=Synchronizing to FDCAN communication; 2=Schedule suspended by gap (In_Gap); 3=Synchronized to schedule (In_Schedule)
  [3:2] MS — Master state
    0=Master_Off, no master properties relevant; 1=Operating as time Slave; 2=Operating as backup time master; 3=Operating as current time master
  [1:0] EL — Error level
    0=Severity 0 - No error; 1=Severity 1 - Warning; 2=Severity 2 - error; 3=Severity 3 - Severe error
0x130 FDCAN_TURNA ro — FDCAN TUR numerator actual register
  [17:0] NAV — Numerator actual value
    0xEFFF=illegal value; 0x21000=illegal value
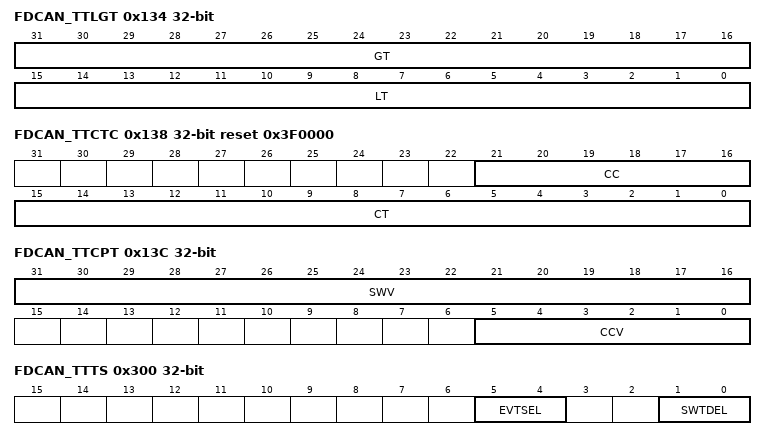
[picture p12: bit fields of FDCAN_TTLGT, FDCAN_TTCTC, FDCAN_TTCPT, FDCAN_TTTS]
0x134 FDCAN_TTLGT ro — FDCAN TT local and global time register
  [31:16] GT — Global time
  [15:0] LT — Local time
0x138 FDCAN_TTCTC ro reset 0x3F0000 — FDCAN TT cycle time and count register
  [21:16] CC — Cycle count
  [15:0] CT — Cycle time
0x13C FDCAN_TTCPT ro — FDCAN TT capture time register
  [31:16] SWV — Stop watch value
  [5:0] CCV — Cycle count value
0x140 FDCAN_TTCSM ro — FDCAN TT cycle sync mark register
  [15:0] CSM — Cycle sync mark
0x300 FDCAN_TTTS — FDCAN TT trigger select register
  [5:4] EVTSEL — Event trigger input selection
    {v}=fdcan1_evt{v} (v=0..3)
  [1:0] SWTDEL — Stop watch trigger input selection
    {v}=fdcan1_swt{v} (v=0..3)
